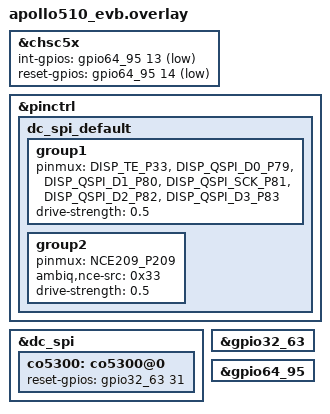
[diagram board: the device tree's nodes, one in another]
/*
 * Copyright (c) 2025 Ambiq Micro Inc.
 *
 * SPDX-License-Identifier: Apache-2.0
 */
#include <apollo510/ambiq-apollo510-pinmux.h>
#include <zephyr/dt-bindings/display/panel.h>
#include <zephyr/dt-bindings/i2c/i2c.h>

&chsc5x {
	int-gpios = <&gpio64_95 13 GPIO_ACTIVE_LOW>;
	reset-gpios = <&gpio64_95 14 GPIO_ACTIVE_LOW>;
};

&pinctrl {
	/* QSPI pinctrl */
	dc_spi_default: dc_spi_default {
		group1 {
			pinmux = <DISP_TE_P33>,
				 <DISP_QSPI_D0_P79>,
				 <DISP_QSPI_D1_P80>,
				 <DISP_QSPI_SCK_P81>,
				 <DISP_QSPI_D2_P82>,
				 <DISP_QSPI_D3_P83>;
			drive-strength = "0.5";
		};

		group2 {
			pinmux = <NCE209_P209>;
			ambiq,nce-src = <0x33>;
			drive-strength = "0.5";
		};
	};
	/* SPI/DSPI pinctrl,co5300 couldn't support SPI.
	 * dc_spi_default: dc_spi_default {
	 *	group1 {
	 *		pinmux = <DISP_TE_P33>,
	 *			<DISP_SPI_SD_P79>,
	 *			<DISP_SPI_DCX_P80>,
	 *			<DISP_SPI_SCK_P81>,
	 *		drive-strength = "0.5";
	 *	};
	 *	group2 {
	 *		pinmux = <NCE209_P209>;
	 *		ambiq,nce-src = <0x32>;
	 *		drive-strength = "0.5";
	 *	};
	 *};
	 */
};

&dc_spi {
	co5300: co5300@0 {
		reset-gpios = <&gpio32_63 31 GPIO_PULL_UP>;
	};
};

&gpio32_63 {
	status = "okay";
};

&gpio64_95 {
	status = "okay";
};

/* SPI variant doesn't use mipi_dsi, so no mipi_dsi config here */
